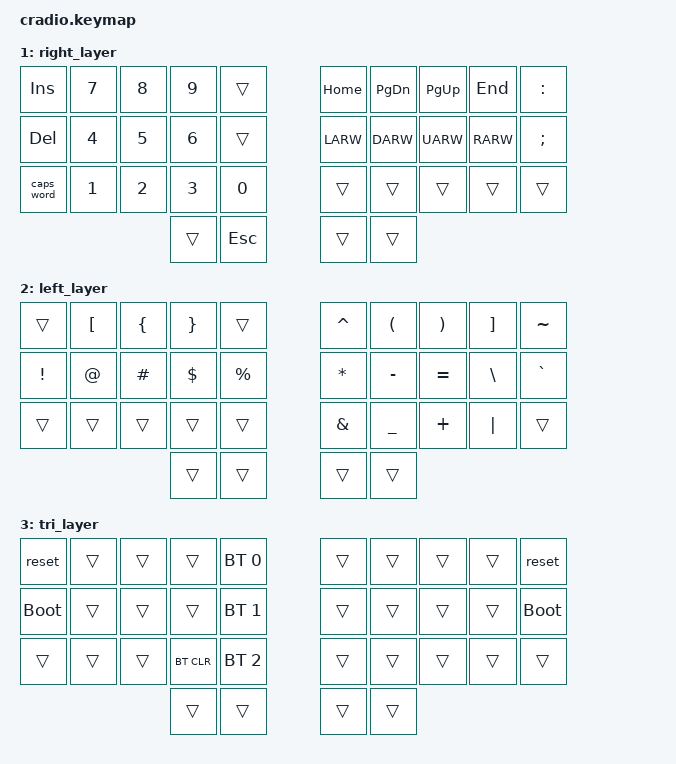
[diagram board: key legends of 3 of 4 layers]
// Copyright (c) 2022 The ZMK Contributors
// SPDX-License-Identifier: MIT

#include <behaviors.dtsi>
#include <dt-bindings/zmk/keys.h>
#include <dt-bindings/zmk/bt.h>

// Home row mods macro
#define HRML(k1,k2,k3,k4) &ht LSHFT k1  &ht LALT k2  &ht LCTRL k3  &ht LGUI k4
#define HRMR(k1,k2,k3,k4) &ht RGUI k1  &ht RCTRL k2  &ht RALT k3  &ht RSHFT k4

#define ________ &trans

&lt {
    flavor = "hold-preferred";
    tapping-term-ms = <220>;
};

&caps_word {
    continue-list = <UNDER MINUS BSPC RSHFT LSHFT>;
};

/ {
    behaviors {
        ht: hold_tap {
            label = "hold_tap";
            compatible = "zmk,behavior-hold-tap";
            #binding-cells = <2>;
            flavor = "tap-preferred";
            tapping-term-ms = <220>;
            quick-tap-ms = <150>;
            global-quick-tap;
            bindings = <&kp>, <&kp>;
        };
    };

    conditional_layers {
        compatible = "zmk,conditional-layers";
        tri_layer {
            if-layers = <1 2>;
            then-layer = <3>;
        };
    };

    keymap {
        compatible = "zmk,keymap";
        default_layer {
            bindings = <
        //╭──────────┬──────────┬──────────┬──────────┬──────────╮   ╭──────────┬──────────┬──────────┬──────────┬──────────╮
            &kp Q      &kp W      &kp E      &kp R      &kp T          &kp Y      &kp U      &kp I      &kp O      &kp P
        //├──────────┼──────────┼──────────┼──────────┼──────────┤   ├──────────┼──────────┼──────────┼──────────┼──────────┤
            HRML(A,        S,         D,         F)     &kp G          &kp H      HRMR(J,        K,         L,        SQT)
        //├──────────┼──────────┼──────────┼──────────┼──────────┤   ├──────────┼──────────┼──────────┼──────────┼──────────┤
            &kp Z      &kp X      &kp C      &kp V      &kp B          &kp N      &kp M      &kp COMMA  &kp DOT    &kp FSLH
        //╰──────────┴──────────┴──────────┼──────────┼──────────┤   ├──────────┼──────────┼──────────┴──────────┴──────────╯
                                            &lt 2 TAB   &kp BSPC     &kp SPACE  &lt 1 ENTER
        //                                 ╰──────────┴──────────╯   ╰──────────┴──────────╯
            >;
        };

        right_layer {
            bindings = <
        //╭──────────┬──────────┬──────────┬──────────┬──────────╮   ╭──────────┬──────────┬──────────┬──────────┬──────────╮
            &kp INS    &kp N7     &kp N8     &kp N9     ________       &kp HOME   &kp PG_DN  &kp PG_UP  &kp END    &kp COLON
        //├──────────┼──────────┼──────────┼──────────┼──────────┤   ├──────────┼──────────┼──────────┼──────────┼──────────┤
            &kp DEL    &kp N4     &kp N5     &kp N6     ________       &kp LARW   &kp DARW   &kp UARW   &kp RARW   &kp SEMI
        //├──────────┼──────────┼──────────┼──────────┼──────────┤   ├──────────┼──────────┼──────────┼──────────┼──────────┤
           &caps_word  &kp N1     &kp N2     &kp N3     &kp N0         ________   ________   ________   ________   ________
        //╰──────────┴──────────┴──────────┼──────────┼──────────┤   ├──────────┼──────────┼──────────┴──────────┴──────────╯
                                             ________   &kp ESC        ________   ________
        //                                 ╰──────────┴──────────╯   ╰──────────┴──────────╯
            >;
        };

        left_layer {
            bindings = <
        //╭──────────┬──────────┬──────────┬──────────┬──────────╮   ╭──────────┬──────────┬──────────┬──────────┬──────────╮
            ________   &kp LBKT   &kp LBRC   &kp RBRC   ________       &kp CARET  &kp LPAR   &kp RPAR   &kp RBKT   &kp TILDE
        //├──────────┼──────────┼──────────┼──────────┼──────────┤   ├──────────┼──────────┼──────────┼──────────┼──────────┤
            &kp EXCL   &kp AT     &kp HASH   &kp DLLR   &kp PRCNT      &kp ASTRK  &kp MINUS  &kp EQUAL  &kp BSLH   &kp GRAVE
        //├──────────┼──────────┼──────────┼──────────┼──────────┤   ├──────────┼──────────┼──────────┼──────────┼──────────┤
            ________   ________   ________   ________   ________       &kp AMPS   &kp UNDER  &kp PLUS   &kp PIPE   ________
        //╰──────────┴──────────┴──────────┼──────────┼──────────┤   ├──────────┼──────────┼──────────┴──────────┴──────────╯
                                             ________   ________       ________   ________
        //                                 ╰──────────┴──────────╯   ╰──────────┴──────────╯
            >;
        };

        tri_layer {
            bindings = <
        //╭──────────┬──────────┬──────────┬──────────┬──────────╮   ╭──────────┬──────────┬──────────┬──────────┬──────────╮
            &reset     ________   ________   ________  &bt BT_SEL 0    ________   ________   ________   ________    &reset
        //├──────────┼──────────┼──────────┼──────────┼──────────┤   ├──────────┼──────────┼──────────┼──────────┼──────────┤
          &bootloader  ________   ________   ________  &bt BT_SEL 1    ________   ________   ________   ________  &bootloader
        //├──────────┼──────────┼──────────┼──────────┼──────────┤   ├──────────┼──────────┼──────────┼──────────┼──────────┤
            ________   ________   ________  &bt BT_CLR &bt BT_SEL 2    ________   ________   ________   ________   ________
        //╰──────────┴──────────┴──────────┼──────────┼──────────┤   ├──────────┼──────────┼──────────┴──────────┴──────────╯
                                             ________   ________       ________   ________
        //                                 ╰──────────┴──────────╯   ╰──────────┴──────────╯
            >;
        };
    };
};
